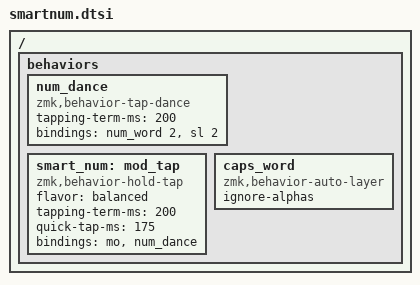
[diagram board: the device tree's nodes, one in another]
// Requires urob autolayer repo

#include <behaviors/num_word.dtsi>

#include <behaviors.dtsi>
#include <dt-bindings/zmk/keys.h>

/ {
    behaviors {
        num_dance: num_dance {
            compatible = "zmk,behavior-tap-dance";
            #binding-cells = <0>;

            tapping-term-ms = <200>;
            bindings = <&num_word 2>, <&sl 2>;
        };
        smart_num: mod_tap {
            compatible = "zmk,behavior-hold-tap";
            #binding-cells = <2>;

            flavor = "balanced";
            tapping-term-ms = <200>;
            quick-tap-ms = <175>;
            bindings = <&mo>, <&num_dance>;
        };

        caps_word: caps_word {
            compatible ="zmk,behavior-auto-layer";
            #binding-cells =<1>;
            ignore-alphas; 
        }
    };
};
